# PIC32CZ2051CA90144 register map
Vendor: Microchip Technology; Series: PIC32CZCA90; File version: 0
CPU: CM7 r1p1, little endian, MPU, FPU, double-precision FPU, I-cache, D-cache, ITCM, DTCM, 3 interrupt priority bits, 222 interrupts
Registers are 32-bit, read-write, reset 0x0 unless marked. A register's access mark holds for its fields unless they carry their own. Offsets are from the block's base; [hi:lo] are bit positions; {n}, {i} and the like mark numbered series; 'fields as' and 'values as' point back to an identical list; <NAME> marks a mode.

## FREQM — Frequency Meter
Base 0x44060000
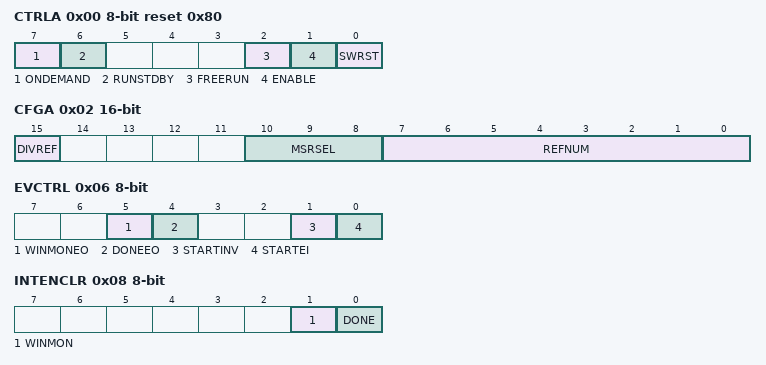
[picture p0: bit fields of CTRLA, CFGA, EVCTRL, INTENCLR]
0x00 CTRLA 8-bit reset 0x80 — Control A Register
  [7] ONDEMAND — On Demand Control
  [6] RUNSTDBY — Run In Standby
  [2] FREERUN — Free Running Mode
  [1] ENABLE
  [0] SWRST — Software Reset
0x01 CTRLB 8-bit wo — Control B Register
  [0] START — Start Measurement
0x02 CFGA 16-bit — Config A Register
  [15] DIVREF — Divide Reference Clock
    0=DIV1 (The reference clock is divided by 1); 1=DIV8 (The reference clock is divided by 8)
  [10:8] MSRSEL — Measurement Clock Selection
    0=GCLK (GCLK Input Clock); 1=CPU (CPU Input Clock)
  [7:0] REFNUM — Number of Reference Clock Cycles
0x04 CTRLC 8-bit — Control C Register
  [2:0] WINMODE — Window Monitor Mode
    0=DISABLE (No window mode (default)); 1=MODE1 (VALUE > WINLT); 2=MODE2 (VALUE < WINUT); 3=MODE3 (WINLT < VALUE < WINUT); 4=MODE4 (!(WINLT < VALUE < WINUT))
0x06 EVCTRL 8-bit — Event Control Register
  [5] WINMONEO — Window Monitor Event Out
  [4] DONEEO — Measurement Done Event Out
  [1] STARTINV — Start Measurement Event Invert Enable
  [0] STARTEI — Start Measurement Event Input Enable
0x08 INTENCLR 8-bit write-1-clears — Interrupt Enable Clear Register
  [1] WINMON — Window Monitor Interrupt Disable
  [0] DONE — Measurement Done Interrupt Disable
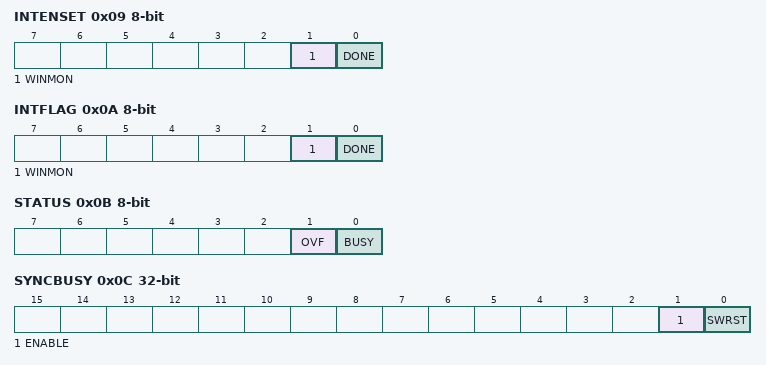
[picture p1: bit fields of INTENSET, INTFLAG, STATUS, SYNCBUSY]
0x09 INTENSET 8-bit write-1-sets — Interrupt Enable Set Register
  [1] WINMON — Window Monitor Interrupt Enable
  [0] DONE — Measurement Done Interrupt Enable
0x0A INTFLAG 8-bit write-1-clears — Interrupt Flag Register
  [1] WINMON — Window Monitor
  [0] DONE — Measurement Done
0x0B STATUS 8-bit
  [1] OVF — Sticky Count Value Overflow
  [0] BUSY — FREQM Status
0x0C SYNCBUSY ro — Synchronization Busy Register
  [1] ENABLE
  [0] SWRST — Software Reset
0x10 VALUE ro — Count Value Register
  [23:0] VALUE — Measurement Value
0x20 WINLT — Window Monitor Lower Threshold
  [23:0] WINLT — Window Lower Threshold
0x24 WINUT — Window Monitor Upper Threshold
  [23:0] WINUT — Window Upper Threshold

## GCLK — Generic Clock Generator
Base 0x44050000
0x00 CTRLA 8-bit — Control
  [0] SWRST — Software Reset
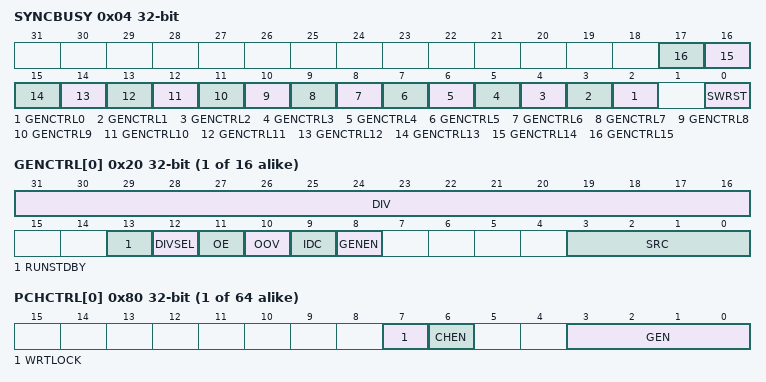
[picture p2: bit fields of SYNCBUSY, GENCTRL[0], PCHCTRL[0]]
0x04 SYNCBUSY ro — Synchronization Busy
  [n+2] GENCTRL{n} (n=0..15) — Generic Clock Generator Control {n} Synchronization Busy bit
  [0] SWRST — Software Reset Synchronization Busy bit
{0x20+4i} GENCTRL[{i}] (i=0..15) — Generic Clock Generator Control
  [31:16] DIV — Division Factor
  [13] RUNSTDBY — Run in Standby
  [12] DIVSEL — Divide Selection
    0=DIV1 (Divide input directly by divider factor); 1=DIV2 (Divide input by 2^(divider factor+ 1))
  [11] OE — Output Enable
  [10] OOV — Output Off Value
  [9] IDC — Improve Duty Cycle
  [8] GENEN — Generic Clock Generator Enable
  [3:0] SRC — Source Select
    0=XOSC (XOSC0 oscillator output); 1=GCLKIN (Generator input pad); 2=GCLKGEN1 (Generic clock generator 1 output); 3=OSCULP32K (OSCULP32K oscillator output); 4=XOSC32K (XOSC32K oscillator output); 5=DFLL (DFLL output); {v}=PLL0_{v-5} (PLL0 output {v-5}) (v=6..9); 10=PLL1_1 (Frac Divider PLL1 output 1); 11=PLL1_2 (Frac Divider PLL1 output 2); 12=PLL1_3 (PLL1 output 3); 13=PLL1_4 (PLL1 output 4)
{0x80+4i} PCHCTRL[{i}] (i=0..63) — Peripheral Clock Control
  [7] WRTLOCK — Write Lock
  [6] CHEN — Channel Enable
  [3:0] GEN — Generic Clock Generator
    {v}=GCLK{v} (Generic clock generator {v}) (v=0..15)

## HSM — Hardware Security Module
Base 0x4F018000
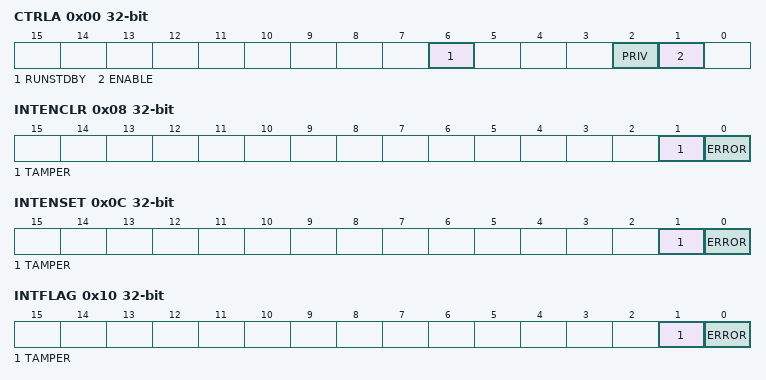
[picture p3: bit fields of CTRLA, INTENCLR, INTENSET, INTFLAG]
0x00 CTRLA — CONTROL REGISTER A
  [6] RUNSTDBY — Run In Standby bit
  [2] PRIV — Privileged Access Only bit
  [1] ENABLE — Clock Enable bit
0x04 CTRLB — CONTROL REGISTER B
  [0] CANCEL — Cancel Command
0x08 INTENCLR write-1-clears — INTERRUPT ENABLE CLEAR REGISTER
  [1] TAMPER — Tamper Interrupt Enable
  [0] ERROR — Error Interrupt Enable
0x0C INTENSET write-1-sets — INTERRUPT ENABLE SET
  fields as INTENCLR
0x10 INTFLAG write-1-clears — INTERRUPT FLAG
  [1] TAMPER — Tamper Interrupt Flag
  [0] ERROR — Error Interrupt Flag
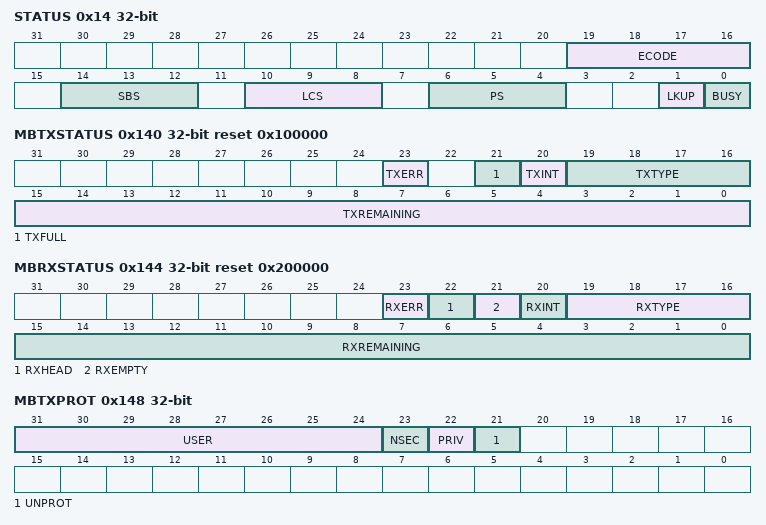
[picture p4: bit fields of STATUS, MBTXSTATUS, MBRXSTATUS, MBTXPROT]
0x14 STATUS
  [19:16] ECODE — ERROR CODE
  [14:12] SBS — SECURE BOOT STATE
  [10:8] LCS — LIFECYCLE STATE
  [6:4] PS — PROCESSING STATE
  [1] LKUP — HSM CPU LOCKUP
  [0] BUSY — HSM CPU BUSY
{0x100+4i} MBFIFO[{i}] (i=0..15) read-modifies — MAILBOX FIFO
  [31:0] MBFIFO
0x140 MBTXSTATUS reset 0x100000 — MAILBOX TRANSMIT STATUS
  [23] TXERR — TRANSMIT ERROR
  [21] TXFULL — TRANSMIT FIFO FULL
  [20] TXINT — TRANSMIT FIFO INTERRUPT FLAG
  [19:16] TXTYPE — TRANSMIT MESSAGE HEADER TYPE
  [15:0] TXREMAINING — TRANSMIT BYTES REMAINING
0x144 MBRXSTATUS reset 0x200000 — MAILBOX RECEIVE STATUS
  [23] RXERR — RECEIVE ERROR
  [22] RXHEAD — Receive Header Next Word bit
  [21] RXEMPTY — RECEIVE FIFO FULL
  [20] RXINT — RECEIVE FIFO INTERRUPT FLAG
  [19:16] RXTYPE — RECEIVE MESSAGE HEADER TYPE
  [15:0] RXREMAINING — RECEIVE BYTES REMAINING
0x148 MBTXPROT — MAILBOX TX PROTECTION
  [31:24] USER — USER SIDEBAND
  [23] NSEC — MAILBOX MESSAGE NON-SECURE ACCESS
  [22] PRIV — MAILBOX MESSAGE PRIVILEDGED ACCESS
  [21] UNPROT — MAILBOX UNPROTECTED
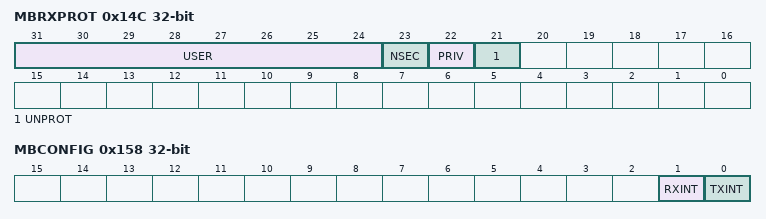
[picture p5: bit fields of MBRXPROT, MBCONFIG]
0x14C MBRXPROT — MAILBOX RX PROTECTION
  fields as MBTXPROT
0x150 MBTXHEAD read-modifies — MAILBOX TRANSMIT HEADER
  [31:0] TXHEAD — MAILBOX TRANSMIT HEADER REGISTER
0x154 MBRXHEAD read-modifies — MAILBOX RECEIVE HEADER
  [31:0] RXHEAD — MAILBOX RECEIVE HEADER REGISTER
0x158 MBCONFIG — MAILBOX CONFIGURATION
  [1] RXINT — MAILBOX RECEIVE INTERRUPT ENABLE
  [0] TXINT — MAILBOX TRANSMIT INTERRUPT ENABLE
